# LSM6DSO_SUBSET register map
File version: 1.0
Accelerometer and gyroscope registers for the SBR IMU (I2C addr 0x6A/0x6B)
CPU: CM33 r0p0, little endian, MPU, FPU, 3 interrupt priority bits
Registers are 8-bit, read-only, reset 0x0 unless marked. A register's access mark holds for its fields unless they carry their own. Offsets are from the block's base; lines under a group give offsets from that group; [hi:lo] are bit positions; {n}, {i} and the like mark numbered series; 'fields as' and 'values as' point back to an identical list; <NAME> marks a mode.

## Memory map
0x00000000 LSM6DSO — iNEMO inertial module: always-on 3D accelerometer and 3D gyroscope

## LSM6DSO — iNEMO inertial module: always-on 3D accelerometer and 3D gyroscope
Base 0x00000000
0x0F WHO_AM_I reset 0x6C — Device identification register. Always reads 0x6C.
  [7:0] ID — Fixed device ID.
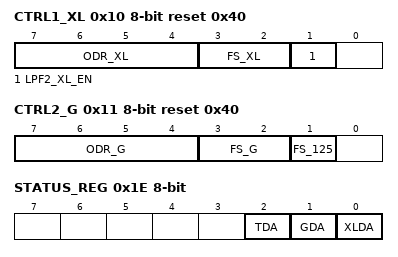
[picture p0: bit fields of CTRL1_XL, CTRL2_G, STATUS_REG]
0x10 CTRL1_XL rw reset 0x40 — Accelerometer control register 1.
  [7:4] ODR_XL — Output data rate / power mode selection.
    0=POWER_DOWN; 1=ODR_12_5Hz (12.5 Hz (low-power)); 2=ODR_26Hz (26 Hz); 3=ODR_52Hz (52 Hz); 4=ODR_104Hz (104 Hz (normal)); 5=ODR_208Hz (208 Hz (normal)); 6=ODR_416Hz (416 Hz (high-perf)); 7=ODR_833Hz (833 Hz (high-perf)); 8=ODR_1666Hz (1666 Hz (high-perf)); 9=ODR_3332Hz (3332 Hz (high-perf)); 10=ODR_6664Hz (6664 Hz (high-perf)); 11=ODR_1_6Hz (1.6 Hz (low-power only))
  [3:2] FS_XL — Full-scale selection.
    0=FS_2G (±2 g); 1=FS_16G (±16 g); 2=FS_4G (±4 g); 3=FS_8G (±8 g)
  [1] LPF2_XL_EN — Second filter selection on output.
0x11 CTRL2_G rw reset 0x40 — Gyroscope control register 2.
  [7:4] ODR_G — Output data rate selection.
    0=POWER_DOWN; 1=ODR_12_5Hz (12.5 Hz); 2=ODR_26Hz (26 Hz); 3=ODR_52Hz (52 Hz); 4=ODR_104Hz (104 Hz (normal)); 5=ODR_208Hz (208 Hz); 6=ODR_416Hz (416 Hz); 7=ODR_833Hz (833 Hz); 8=ODR_1666Hz (1666 Hz); 9=ODR_3332Hz (3332 Hz); 10=ODR_6664Hz (6664 Hz)
  [3:2] FS_G — Full-scale selection.
    0=FS_250DPS (±250 dps); 1=FS_500DPS (±500 dps); 2=FS_1000DPS (±1000 dps); 3=FS_2000DPS (±2000 dps)
  [1] FS_125 — Select gyroscope 125 dps full-scale.
0x1E STATUS_REG — Status register. Flags cleared on reading output data.
  [2] TDA — Temperature new data available.
  [1] GDA — Gyroscope new data available.
  [0] XLDA — Accelerometer new data available.
0x22 OUTX_L_G — Gyroscope X-axis low byte.
0x23 OUTX_H_G — Gyroscope X-axis high byte.
0x24 OUTY_L_G — Gyroscope Y-axis low byte.
0x25 OUTY_H_G — Gyroscope Y-axis high byte.
0x26 OUTZ_L_G — Gyroscope Z-axis low byte.
0x27 OUTZ_H_G — Gyroscope Z-axis high byte.
0x28 OUTX_L_A — Accelerometer X-axis low byte.
0x29 OUTX_H_A — Accelerometer X-axis high byte.
0x2A OUTY_L_A — Accelerometer Y-axis low byte.
0x2B OUTY_H_A — Accelerometer Y-axis high byte.
0x2C OUTZ_L_A — Accelerometer Z-axis low byte.
0x2D OUTZ_H_A — Accelerometer Z-axis high byte.
